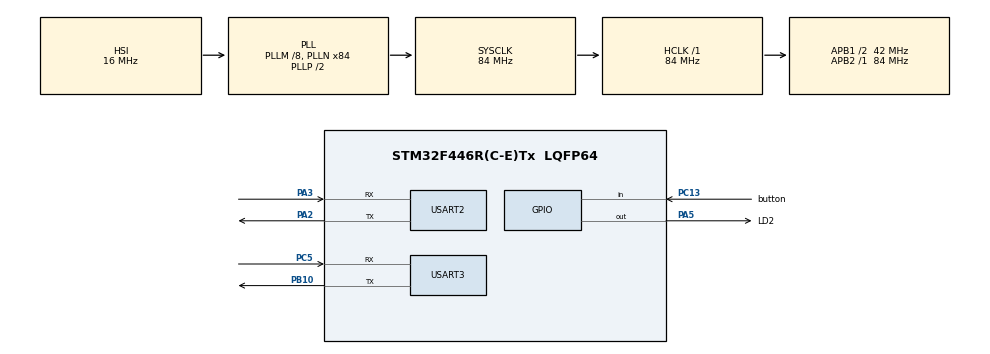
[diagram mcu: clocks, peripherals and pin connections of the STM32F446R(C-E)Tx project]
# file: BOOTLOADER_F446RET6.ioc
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Mcu.Family=STM32F4
Mcu.Name=STM32F446R(C-E)Tx
Mcu.Package=LQFP64
NVIC.PriorityGroup=NVIC_PRIORITYGROUP_4
PA2.Mode=Asynchronous
PA2.Signal=USART2_TX
PA3.Mode=Asynchronous
PA3.Signal=USART2_RX
PA5.GPIO_Label=LD2
PA5.Signal=GPIO_Output
PB10.Mode=Asynchronous
PB10.Signal=USART3_TX
PC13.GPIO_Label=button
PC13.GPIO_PuPd=GPIO_PULLDOWN
PC13.Signal=GPIO_Input
PC14-OSC32_IN.Mode=LSE-External-Oscillator
PC14-OSC32_IN.Signal=RCC_OSC32_IN
PC15-OSC32_OUT.Mode=LSE-External-Oscillator
PC15-OSC32_OUT.Signal=RCC_OSC32_OUT
PC5.Mode=Asynchronous
PC5.Signal=USART3_RX
PH0-OSC_IN.Mode=HSE-External-Oscillator
PH0-OSC_IN.Signal=RCC_OSC_IN
PH1-OSC_OUT.Mode=HSE-External-Oscillator
PH1-OSC_OUT.Signal=RCC_OSC_OUT
ProjectManager.HeapSize=0x200
ProjectManager.StackSize=0x400
ProjectManager.TargetToolchain=STM32CubeIDE
RCC.AHBFreq_Value=84000000
RCC.APB1CLKDivider=RCC_HCLK_DIV2
RCC.APB1Freq_Value=42000000
RCC.APB1TimFreq_Value=84000000
RCC.APB2Freq_Value=84000000
RCC.APB2TimFreq_Value=84000000
RCC.CortexFreq_Value=84000000
RCC.HCLKFreq_Value=84000000
RCC.PLLM=8
RCC.PLLN=84
RCC.SYSCLKFreq_VALUE=84000000
RCC.SYSCLKSource=RCC_SYSCLKSOURCE_PLLCLK
RCC.USBFreq_Value=84000000
RCC.VCOOutputFreq_Value=168000000
USART2.VirtualMode=VM_ASYNC
USART3.VirtualMode=VM_ASYNC
VP_CRC_VS_CRC.Mode=CRC_Activate
board=custom

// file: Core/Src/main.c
/* USER CODE BEGIN Header */
/**
  ******************************************************************************
  * @file           : main.c
  * @brief          : Main program body
  ******************************************************************************
  * @attention
  *
  * Copyright (c) 2025 STMicroelectronics.
  * All rights reserved.
  *
  * This software is licensed under terms that can be found in the LICENSE file
  * in the root directory of this software component.
  * If no LICENSE file comes with this software, it is provided AS-IS.
  *
  ******************************************************************************
  */
/* USER CODE END Header */
#include "main.h"

/* USER CODE BEGIN Includes */
#include <stdio.h>
#include <stdint.h>
#include <stdarg.h>
#include <string.h>
/* USER CODE END Includes */

/* USER CODE BEGIN PD */

#define BL_GET_VER            0x51
#define BL_GET_HELP           0x52
#define BL_GET_CID            0x53
#define BL_GET_RDP_STATUS     0x54
#define BL_GO_TO_ADDR         0x55
#define BL_FLASH_ERASE        0x56
#define BL_MEM_WRITE          0x57
#define BL_EN_RW_PROTECT      0x58
#define BL_MEM_READ           0x59
#define BL_READ_SECTOR_STATUS 0x5A
#define BL_OTP_READ           0x5B
#define BL_DIS_R_W_PROTECT    0x5C

#define BL_RX_LEN             200
/* USER CODE END PD */

CRC_HandleTypeDef hcrc;

UART_HandleTypeDef huart2;
UART_HandleTypeDef huart3;

/* USER CODE BEGIN PV */
uint8_t bl_rx_buffer[BL_RX_LEN];
/* USER CODE END PV */

void SystemClock_Config(void);
static void MX_GPIO_Init(void);
static void MX_USART2_UART_Init(void);
static void MX_USART3_UART_Init(void);
static void MX_CRC_Init(void);
/* USER CODE BEGIN PFP */
void bootloader_jump_to_application(void);
void bootloader_read_uart_data(void);
void bootloader_handle_read_otp(uint8_t *bl_rx_buffer);
void bootloader_handle_read_sector_status(uint8_t *bl_rx_buffer);
void bootloader_handle_mem_read(uint8_t *bl_rx_buffer);
void bootloader_handle_endis_rw_protect(uint8_t *bl_rx_buffer);
void bootloader_handle_mem_write_cmd(uint8_t *bl_rx_buffer);
void bootloader_handle_flash_erase_cmd(uint8_t *bl_rx_buffer);
void bootloader_handle_go_cmd(uint8_t *bl_rx_buffer);
void bootloader_handle_getrdp_cmd(uint8_t *bl_rx_buffer);
void bootloader_handle_getcid_cmd(uint8_t *bl_rx_buffer);
void bootloader_handle_gethelp_cmd(uint8_t *bl_rx_buffer);
void bootloader_handle_getver_cmd(uint8_t *bl_rx_buffer);

/* USER CODE END PFP */

int main(void)
{

  /* MCU Configuration--------------------------------------------------------*/

  /* Reset of all peripherals, Initializes the Flash interface and the Systick. */
  HAL_Init();

  /* Configure the system clock */
  SystemClock_Config();

  /* Initialize all configured peripherals */
  MX_GPIO_Init();
  MX_USART2_UART_Init();
  MX_USART3_UART_Init();
  MX_CRC_Init();
  /* USER CODE BEGIN 2 */
  printf("Bootloader ready...\n");
  if (HAL_GPIO_ReadPin(button_GPIO_Port, button_Pin) == GPIO_PIN_RESET)
  {
	  printf("Button is pressed...going to bootloader mode\n\r");
	  bootloader_read_uart_data();
  }
  else
  {
	  printf("button is not pressed...execute application code\n\r");
	  bootloader_jump_to_application();
  }
  /* USER CODE END 2 */

  /* Infinite loop */
  while (1)
  {

  }
}

void SystemClock_Config(void)
{
  RCC_OscInitTypeDef RCC_OscInitStruct = {0};
  RCC_ClkInitTypeDef RCC_ClkInitStruct = {0};

  /** Configure the main internal regulator output voltage
  */
  __HAL_RCC_PWR_CLK_ENABLE();
  __HAL_PWR_VOLTAGESCALING_CONFIG(PWR_REGULATOR_VOLTAGE_SCALE3);

  /** Initializes the RCC Oscillators according to the specified parameters
  * in the RCC_OscInitTypeDef structure.
  */
  RCC_OscInitStruct.OscillatorType = RCC_OSCILLATORTYPE_HSI;
  RCC_OscInitStruct.HSIState = RCC_HSI_ON;
  RCC_OscInitStruct.HSICalibrationValue = RCC_HSICALIBRATION_DEFAULT;
  RCC_OscInitStruct.PLL.PLLState = RCC_PLL_ON;
  RCC_OscInitStruct.PLL.PLLSource = RCC_PLLSOURCE_HSI;
  RCC_OscInitStruct.PLL.PLLM = 8;
  RCC_OscInitStruct.PLL.PLLN = 84;
  RCC_OscInitStruct.PLL.PLLP = RCC_PLLP_DIV2;
  RCC_OscInitStruct.PLL.PLLQ = 2;
  RCC_OscInitStruct.PLL.PLLR = 2;
  if (HAL_RCC_OscConfig(&RCC_OscInitStruct) != HAL_OK)
  {
    Error_Handler();
  }

  /** Initializes the CPU, AHB and APB buses clocks
  */
  RCC_ClkInitStruct.ClockType = RCC_CLOCKTYPE_HCLK|RCC_CLOCKTYPE_SYSCLK
                              |RCC_CLOCKTYPE_PCLK1|RCC_CLOCKTYPE_PCLK2;
  RCC_ClkInitStruct.SYSCLKSource = RCC_SYSCLKSOURCE_PLLCLK;
  RCC_ClkInitStruct.AHBCLKDivider = RCC_SYSCLK_DIV1;
  RCC_ClkInitStruct.APB1CLKDivider = RCC_HCLK_DIV2;
  RCC_ClkInitStruct.APB2CLKDivider = RCC_HCLK_DIV1;

  if (HAL_RCC_ClockConfig(&RCC_ClkInitStruct, FLASH_LATENCY_2) != HAL_OK)
  {
    Error_Handler();
  }
}

static void MX_CRC_Init(void)
{

  hcrc.Instance = CRC;
  if (HAL_CRC_Init(&hcrc) != HAL_OK)
  {
    Error_Handler();
  }

}

static void MX_USART2_UART_Init(void)
{

  huart2.Instance = USART2;
  huart2.Init.BaudRate = 115200;
  huart2.Init.WordLength = UART_WORDLENGTH_8B;
  huart2.Init.StopBits = UART_STOPBITS_1;
  huart2.Init.Parity = UART_PARITY_NONE;
  huart2.Init.Mode = UART_MODE_TX_RX;
  huart2.Init.HwFlowCtl = UART_HWCONTROL_NONE;
  huart2.Init.OverSampling = UART_OVERSAMPLING_16;
  if (HAL_UART_Init(&huart2) != HAL_OK)
  {
    Error_Handler();
  }

}

static void MX_USART3_UART_Init(void)
{

  huart3.Instance = USART3;
  huart3.Init.BaudRate = 115200;
  huart3.Init.WordLength = UART_WORDLENGTH_8B;
  huart3.Init.StopBits = UART_STOPBITS_1;
  huart3.Init.Parity = UART_PARITY_NONE;
  huart3.Init.Mode = UART_MODE_TX_RX;
  huart3.Init.HwFlowCtl = UART_HWCONTROL_NONE;
  huart3.Init.OverSampling = UART_OVERSAMPLING_16;
  if (HAL_UART_Init(&huart3) != HAL_OK)
  {
    Error_Handler();
  }

}

static void MX_GPIO_Init(void)
{
  GPIO_InitTypeDef GPIO_InitStruct = {0};

  /* GPIO Ports Clock Enable */
  __HAL_RCC_GPIOC_CLK_ENABLE();
  __HAL_RCC_GPIOH_CLK_ENABLE();
  __HAL_RCC_GPIOA_CLK_ENABLE();
  __HAL_RCC_GPIOB_CLK_ENABLE();

  /*Configure GPIO pin Output Level */
  HAL_GPIO_WritePin(LED_GPIO_Port, LED_Pin, GPIO_PIN_RESET);

  /*Configure GPIO pin : button_Pin */
  GPIO_InitStruct.Pin = button_Pin;
  GPIO_InitStruct.Mode = GPIO_MODE_INPUT;
  GPIO_InitStruct.Pull = GPIO_PULLDOWN;
  HAL_GPIO_Init(button_GPIO_Port, &GPIO_InitStruct);

  /*Configure GPIO pin : LED_Pin */
  GPIO_InitStruct.Pin = LED_Pin;
  GPIO_InitStruct.Mode = GPIO_MODE_OUTPUT_PP;
  GPIO_InitStruct.Pull = GPIO_NOPULL;
  GPIO_InitStruct.Speed = GPIO_SPEED_FREQ_LOW;
  HAL_GPIO_Init(LED_GPIO_Port, &GPIO_InitStruct);

}

/* USER CODE BEGIN 4 */

void bootloader_read_uart_data(void)
{
	uint8_t rcv_len = 0;
	while(1)
	{
		memset(bl_rx_buffer, 0, 200);
		HAL_UART_Receive(&huart3, &bl_rx_buffer, 1, HAL_MAX_DELAY);
		rcv_len = bl_rx_buffer[0];
		HAL_UART_Receive(&huart3, &bl_rx_buffer[1], rcv_len, HAL_MAX_DELAY);
		switch(bl_rx_buffer[1])
		{
			case BL_GET_VER:
				bootloader_handle_getver_cmd(bl_rx_buffer);
				break;
			case BL_GET_HELP:
				bootloader_handle_gethelp_cmd(bl_rx_buffer);
				break;
			case BL_GET_CID:
				bootloader_handle_getcid_cmd(bl_rx_buffer);
				break;
			case BL_GET_RDP_STATUS:
				bootloader_handle_getrdp_cmd(bl_rx_buffer);
		 	    break;
			case BL_GO_TO_ADDR:
				bootloader_handle_go_cmd(bl_rx_buffer);
				break;
			case BL_FLASH_ERASE:
				bootloader_handle_flash_erase_cmd(bl_rx_buffer);
				break;
			case BL_MEM_WRITE:
				bootloader_handle_mem_write_cmd(bl_rx_buffer);
				break;
			case BL_EN_RW_PROTECT:
				bootloader_handle_endis_rw_protect(bl_rx_buffer);
				break;
			case BL_MEM_READ:
				bootloader_handle_mem_read(bl_rx_buffer);
				break;
			case BL_READ_SECTOR_STATUS:
				bootloader_handle_read_sector_status(bl_rx_buffer);
				break;
			case BL_OTP_READ:
				bootloader_handle_read_otp(bl_rx_buffer);
				break;
			default:

		}
	}
}

void bootloader_jump_to_application(void)
{
	printf("jumping to user application...\n");
	void (*app_reset_handler)(void) = (void*)(*((volatile uint32_t*) (0x08008000 + 4U)));
    printf("app reset handler addr:%#lx\n", app_reset_handler);
	  /* Reset the Clock */
	  HAL_RCC_DeInit();
	  HAL_DeInit();
	  __set_MSP(*(volatile uint32_t*) 0x08008000);
	  SysTick->CTRL = 0;
	  SysTick->LOAD = 0;
	  SysTick->VAL = 0;

	  /* Jump to application */
	  app_reset_handler();
}

void bootloader_handle_read_otp(uint8_t *bl_rx_buffer)
{

}

void bootloader_handle_read_sector_status(uint8_t *bl_rx_buffer)
{

}

void bootloader_handle_mem_read(uint8_t *bl_rx_buffer)
{

}

void bootloader_handle_endis_rw_protect(uint8_t *bl_rx_buffer)
{

}

void bootloader_handle_mem_write_cmd(uint8_t *bl_rx_buffer)
{

}

void bootloader_handle_flash_erase_cmd(uint8_t *bl_rx_buffer)
{

}

void bootloader_handle_go_cmd(uint8_t *bl_rx_buffer)
{

}

void bootloader_handle_getrdp_cmd(uint8_t *bl_rx_buffer)
{

}

void bootloader_handle_getcid_cmd(uint8_t *bl_rx_buffer)
{

}

void bootloader_handle_gethelp_cmd(uint8_t *bl_rx_buffer)
{

}

void bootloader_handle_getver_cmd(uint8_t *bl_rx_buffer)
{

}

#define PRINTF   int __io_putchar(int ch)
PRINTF
{
	HAL_UART_Transmit(&huart2, (uint8_t*)&ch, 1, HAL_MAX_DELAY);
	return ch;
}
/* USER CODE END 4 */

void Error_Handler(void)
{
  __disable_irq();
  while (1)
  {
  }
}
